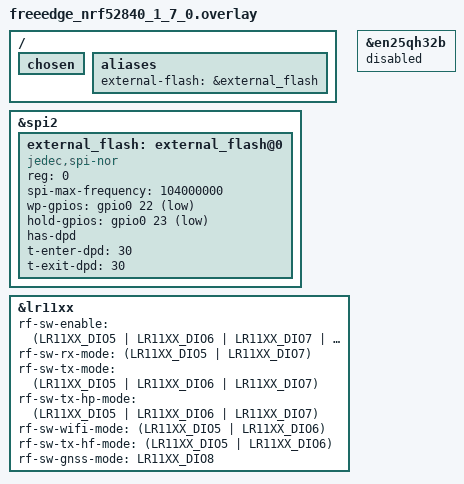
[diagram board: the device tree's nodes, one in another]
/ {
    chosen{
        /delete-property/ nordic,pm-ext-flash;
    };

    aliases{
        external-flash = &external_flash;
    };
};

&spi2{
    external_flash: external_flash@0{
        compatible = "jedec,spi-nor";
        reg = <0>;
        spi-max-frequency = <104000000>;

        wp-gpios = <&gpio0 22 GPIO_ACTIVE_LOW>;
        hold-gpios = <&gpio0 23 GPIO_ACTIVE_LOW>;
        has-dpd;
        t-enter-dpd = <30>;
        t-exit-dpd = <30>;
    };
};

&lr11xx {
    rf-sw-enable = <(LR11XX_DIO5 | LR11XX_DIO6 | LR11XX_DIO7 | LR11XX_DIO8)>;    /* all DIOs used */
    rf-sw-rx-mode = <(LR11XX_DIO5 | LR11XX_DIO7)>;    /* receive - LNA_LF0 path active */
    rf-sw-tx-mode = <(LR11XX_DIO5 | LR11XX_DIO6 | LR11XX_DIO7)>;    /* send - PA_HP_LF active */
    rf-sw-tx-hp-mode = <(LR11XX_DIO5 | LR11XX_DIO6 | LR11XX_DIO7)>;    /* same as tx because RFO_HP_LF is connected to RF switch */
    rf-sw-wifi-mode = <(LR11XX_DIO5 | LR11XX_DIO6)>;    /* WIFI_ANT path (High frequency RX) - selected 2.0G path */
    rf-sw-tx-hf-mode = <(LR11XX_DIO5 | LR11XX_DIO6)>;    /* Same as Wifi path (HF TX), locked on 2.0G for now */
    rf-sw-gnss-mode = <LR11XX_DIO8>;  /* GPS_LNA enable */
};

&en25qh32b{
    status = "disabled";
};
